# STM32F301 register map
File version: 1.9
CPU: CM4 r1p0, little endian, MPU, FPU, 4 interrupt priority bits
Registers are 32-bit, read-write, reset 0x0 unless marked. A register's access mark holds for its fields unless they carry their own. Offsets are from the block's base; [hi:lo] are bit positions; {n}, {i} and the like mark numbered series; 'fields as' and 'values as' point back to an identical list.

## ADC1_2 — ADC Common registers
Base 0x50000300
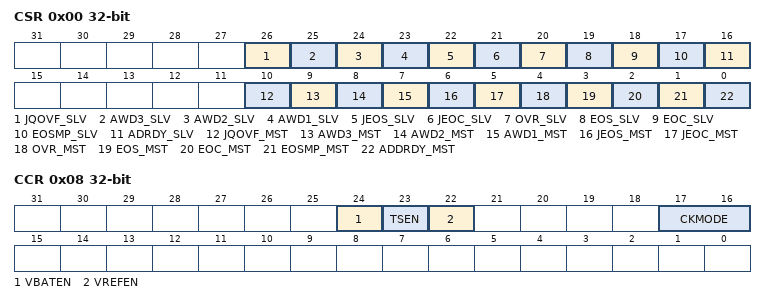
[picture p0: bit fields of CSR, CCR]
0x00 CSR ro — ADC Common status register
  [26] JQOVF_SLV — Injected Context Queue Overflow flag of the slave ADC
    0=NoOverflow (No injected context queue overflow has occurred); 1=Overflow (Injected context queue overflow has occurred)
  [25] AWD3_SLV — Analog watchdog 3 flag of the slave ADC
    0=NoEvent (No analog watchdog event occurred); 1=Event (Analog watchdog event occurred)
  [24] AWD2_SLV — Analog watchdog 2 flag of the slave ADC
    values as AWD3_SLV
  [23] AWD1_SLV — Analog watchdog 1 flag of the slave ADC
    values as AWD3_SLV
  [22] JEOS_SLV — End of injected sequence flag of the slave ADC
    0=NotComplete (Injected sequence is not complete); 1=Complete (Injected sequence complete)
  [21] JEOC_SLV — End of injected conversion flag of the slave ADC
    0=NotComplete (Injected conversion is not complete); 1=Complete (Injected conversion complete)
  [20] OVR_SLV — Overrun flag of the slave ADC
    0=No overrun occurred; 1=Overrun occurred
  [19] EOS_SLV — End of regular sequence flag of the slave ADC
    0=NotComplete (Regular sequence is not complete); 1=Complete (Regular sequence complete)
  [18] EOC_SLV — End of regular conversion of the slave ADC
    0=NotComplete (Regular conversion is not complete); 1=Complete (Regular conversion complete)
  [17] EOSMP_SLV
    0=NotEnded (End of sampling phase no yet reached); 1=Ended (End of sampling phase reached)
  [16] ADRDY_SLV
    0=NotReady (ADC is not ready to start conversion); 1=Ready (ADC is ready to start conversion)
  [10] JQOVF_MST
    values as JQOVF_SLV
  [9] AWD3_MST
    values as AWD3_SLV
  [8] AWD2_MST
    values as AWD3_SLV
  [7] AWD1_MST
    values as AWD3_SLV
  [6] JEOS_MST
    values as JEOS_SLV
  [5] JEOC_MST
    values as JEOC_SLV
  [4] OVR_MST
    0=No overrun occurred; 1=Overrun occurred
  [3] EOS_MST
    values as EOS_SLV
  [2] EOC_MST
    values as EOC_SLV
  [1] EOSMP_MST
    values as EOSMP_SLV
  [0] ADDRDY_MST
0x08 CCR — ADC common control register
  [24] VBATEN — VBAT enable
    0=Disabled (V_BAT channel disabled); 1=Enabled (V_BAT channel enabled)
  [23] TSEN — Temperature sensor enable
    0=Disabled (Temperature sensor channel disabled); 1=Enabled (Temperature sensor channel enabled)
  [22] VREFEN — VREFINT enable
    0=Disabled (V_REFINT channel disabled); 1=Enabled (V_REFINT channel enabled)
  [17:16] CKMODE — ADC clock mode
    0=Asynchronous (Use Kernel Clock adc_ker_ck_input divided by PRESC. Asynchronous to AHB clock); 1=SyncDiv1 (Use AHB clock rcc_hclk3. In this case rcc_hclk must equal sys_d1cpre_ck); 2=SyncDiv2 (Use AHB clock rcc_hclk3 divided by 2); 3=SyncDiv4 (Use AHB clock rcc_hclk3 divided by 4)

## EXTI — External interrupt/event controller
Base 0x40010400
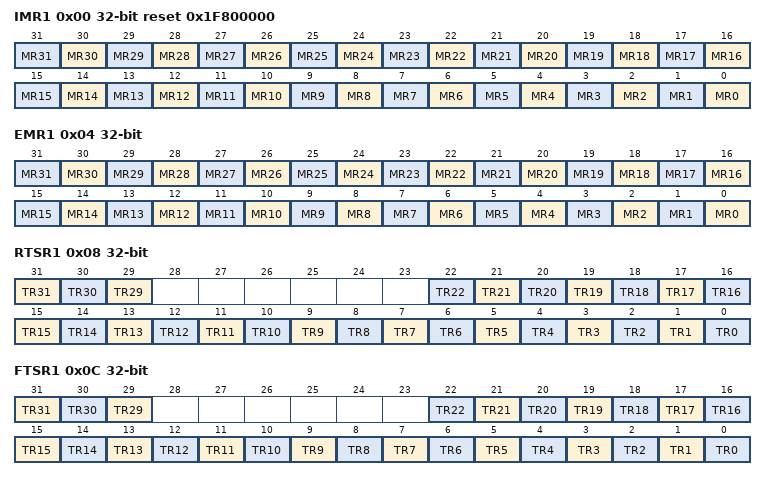
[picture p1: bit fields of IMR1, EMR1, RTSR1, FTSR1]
0x00 IMR1 reset 0x1F800000 — Interrupt mask register
  [all] fields
    0=Masked (Interrupt request line is masked); 1=Unmasked (Interrupt request line is unmasked)
  [n] MR{n} (n=0..31) — Interrupt Mask on line {n}
0x04 EMR1 — Event mask register
  [all] fields
    0=Masked (Event request line is masked); 1=Unmasked (Event request line is unmasked)
  [n] MR{n} (n=0..31) — Event Mask on line {n}
0x08 RTSR1 — Rising Trigger selection register
  [all] fields
    0=Disabled (Rising edge trigger is disabled); 1=Enabled (Rising edge trigger is enabled)
  [31] TR31 — Rising trigger event configuration of line 31
  [30] TR30 — Rising trigger event configuration of line 30
  [29] TR29 — Rising trigger event configuration of line 29
  [n] TR{n} (n=0..22) — Rising trigger event configuration of line {n}
0x0C FTSR1 — Falling Trigger selection register
  [all] fields
    0=Disabled (Falling edge trigger is disabled); 1=Enabled (Falling edge trigger is enabled)
  [31] TR31 — Falling trigger event configuration of line 31
  [30] TR30 — Falling trigger event configuration of line 30.
  [29] TR29 — Falling trigger event configuration of line 29
  [n] TR{n} (n=0..22) — Falling trigger event configuration of line {n}
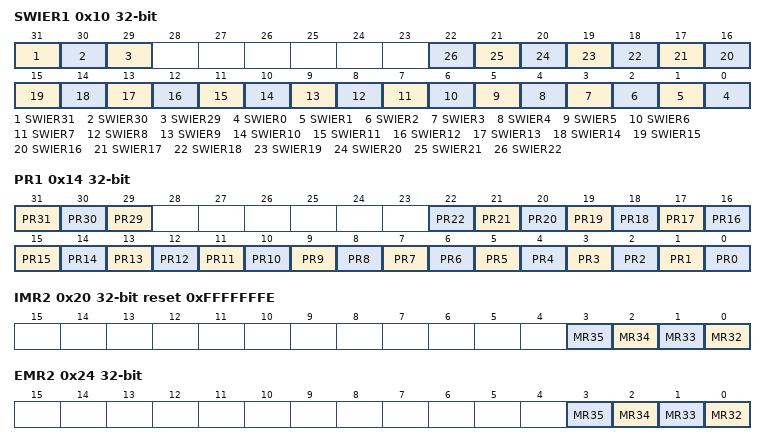
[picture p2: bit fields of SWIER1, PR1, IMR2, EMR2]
0x10 SWIER1 — Software interrupt event register
  [all] fields
    on write: 1=Pend (Generates an interrupt request)
  [31] SWIER31 — Software Interrupt on line 319
  [30] SWIER30 — Software Interrupt on line 309
  [29] SWIER29 — Software Interrupt on line 29
  [n] SWIER{n} (n=0..22) — Software Interrupt on line {n}
0x14 PR1 — Pending register
  [all] fields
    on read: 0=NotPending (No trigger request occurred); 1=Pending (Selected trigger request occurred) | on write: 1=Clears pending bit
  [31] PR31 write-1-clears — Pending bit 31
  [30] PR30 write-1-clears — Pending bit 30
  [29] PR29 write-1-clears — Pending bit 29
  [n] PR{n} write-1-clears (n=0..22) — Pending bit {n}
0x20 IMR2 reset 0xFFFFFFFE — Interrupt mask register
  [all] fields
    values as the fields of IMR1
  [n-32] MR{n} (n=32..35) — Interrupt Mask on external/internal line {n}
0x24 EMR2 — Event mask register
  [all] fields
    values as the fields of EMR1
  [n-32] MR{n} (n=32..35) — Event mask on external/internal line {n}
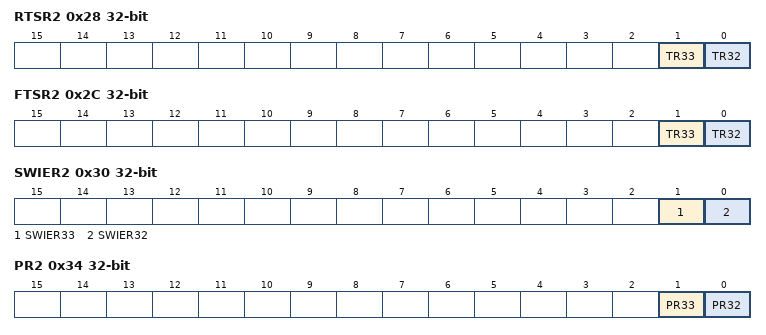
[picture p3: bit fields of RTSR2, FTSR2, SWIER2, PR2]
0x28 RTSR2 — Rising Trigger selection register
  [1] TR33 — Rising trigger event configuration bit of line 33
    values as the fields of RTSR1
  [0] TR32 — Rising trigger event configuration bit of line 32
    values as the fields of RTSR1
0x2C FTSR2 — Falling Trigger selection register
  [1] TR33 — Falling trigger event configuration bit of line 33
    values as the fields of FTSR1
  [0] TR32 — Falling trigger event configuration bit of line 32
    values as the fields of FTSR1
0x30 SWIER2 — Software interrupt event register
  [1] SWIER33 — Software interrupt on line 33
    on write: 1=Pend (Generates an interrupt request)
  [0] SWIER32 — Software interrupt on line 32
    on write: 1=Pend (Generates an interrupt request)
0x34 PR2 — Pending register
  [1] PR33 write-1-clears — Pending bit on line 33
    values as the fields of PR1
  [0] PR32 write-1-clears — Pending bit on line 32
    values as the fields of PR1
